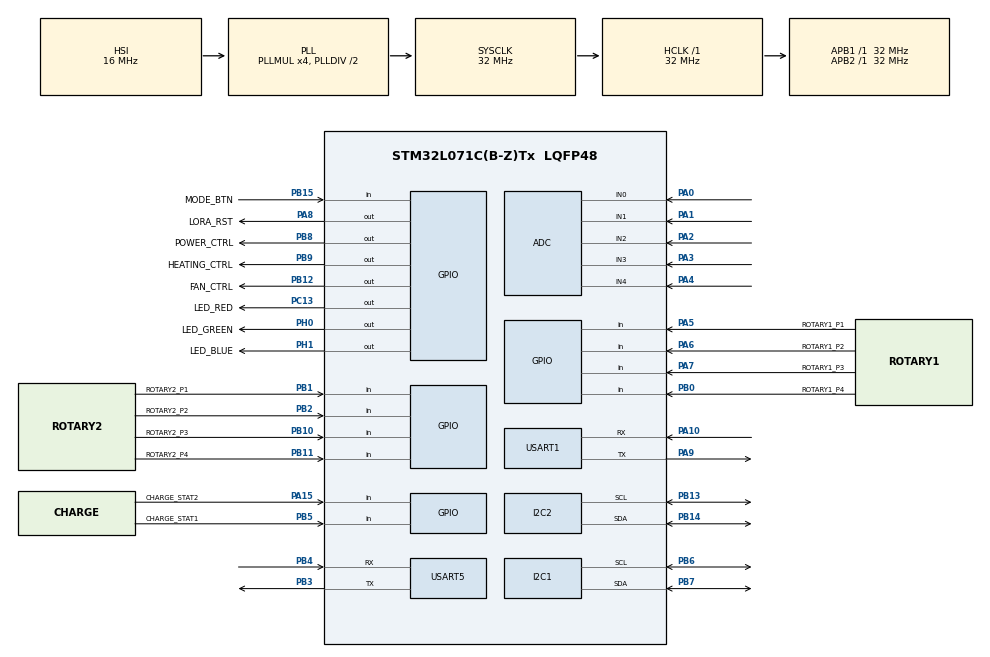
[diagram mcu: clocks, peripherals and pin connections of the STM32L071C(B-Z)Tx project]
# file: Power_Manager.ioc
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ADC.ClockPrescaler=ADC_CLOCK_ASYNC_DIV4
ADC.ContinuousConvMode=DISABLE
ADC.DMAContinuousRequests=DISABLE
ADC.DiscontinuousConvMode=DISABLE
ADC.EOCSelection=ADC_EOC_SEQ_CONV
ADC.EnableAnalogWatchDog=false
ADC.ExternalTrigConv=ADC_EXTERNALTRIGCONV_T3_TRGO
ADC.LowPowerAutoPowerOff=DISABLE
ADC.OversamplingMode=DISABLE
ADC.SamplingTime=ADC_SAMPLETIME_7CYCLES_5
ADC.ScanConvMode=ADC_SCAN_DIRECTION_FORWARD
Dma.ADC.0.Direction=DMA_PERIPH_TO_MEMORY
Dma.ADC.0.Instance=DMA1_Channel1
Dma.ADC.0.MemDataAlignment=DMA_MDATAALIGN_HALFWORD
Dma.ADC.0.MemInc=DMA_MINC_ENABLE
Dma.ADC.0.Mode=DMA_NORMAL
Dma.ADC.0.PeriphDataAlignment=DMA_PDATAALIGN_HALFWORD
Dma.ADC.0.PeriphInc=DMA_PINC_DISABLE
Dma.ADC.0.Priority=DMA_PRIORITY_LOW
Dma.Request0=ADC
I2C1.Timing=0x00707CBB
I2C2.Timing=0x00707CBB
Mcu.Family=STM32L0
Mcu.Name=STM32L071C(B-Z)Tx
Mcu.Package=LQFP48
NVIC.DMA1_Channel1_IRQn=true\:0\:0\:false\:false\:true\:false\:true
NVIC.TIM6_IRQn=true\:0\:0\:false\:false\:true\:true\:true
NVIC.TIM7_IRQn=true\:0\:0\:false\:false\:true\:true\:true
NVIC.USART1_IRQn=true\:0\:0\:false\:false\:true\:true\:true
NVIC.USART4_5_IRQn=true\:0\:0\:false\:false\:true\:true\:true
PA0.Mode=IN0
PA0.Signal=ADC_IN0
PA1.Mode=IN1
PA1.Signal=ADC_IN1
PA10.Mode=Asynchronous
PA10.Signal=USART1_RX
PA13.Mode=Serial_Wire
PA13.Signal=SYS_SWDIO
PA14.Mode=Serial_Wire
PA14.Signal=SYS_SWCLK
PA15.GPIO_Label=CHARGE_STAT2
PA15.Signal=GPIO_Input
PA2.Mode=IN2
PA2.Signal=ADC_IN2
PA3.Mode=IN3
PA3.Signal=ADC_IN3
PA4.Mode=IN4
PA4.Signal=ADC_IN4
PA5.GPIO_Label=ROTARY1_P1
PA5.Signal=GPIO_Input
PA6.GPIO_Label=ROTARY1_P2
PA6.Signal=GPIO_Input
PA7.GPIO_Label=ROTARY1_P3
PA7.Signal=GPIO_Input
PA8.GPIO_Label=LORA_RST
PA8.Signal=GPIO_Output
PA9.Mode=Asynchronous
PA9.Signal=USART1_TX
PB0.GPIO_Label=ROTARY1_P4
PB0.Signal=GPIO_Input
PB1.GPIO_Label=ROTARY2_P1
PB1.Signal=GPIO_Input
PB10.GPIO_Label=ROTARY2_P3
PB10.Signal=GPIO_Input
PB11.GPIO_Label=ROTARY2_P4
PB11.Signal=GPIO_Input
PB12.GPIO_Label=FAN_CTRL
PB12.GPIO_ModeDefaultOutputPP=GPIO_MODE_OUTPUT_PP
PB12.GPIO_PuPd=GPIO_PULLUP
PB12.PinState=GPIO_PIN_RESET
PB12.Signal=GPIO_Output
PB13.Mode=I2C
PB13.Signal=I2C2_SCL
PB14.Mode=I2C
PB14.Signal=I2C2_SDA
PB15.GPIO_Label=MODE_BTN
PB15.GPIO_PuPd=GPIO_PULLUP
PB15.Signal=GPIO_Input
PB2.GPIO_Label=ROTARY2_P2
PB2.Signal=GPIO_Input
PB3.Mode=Asynchronous
PB3.Signal=USART5_TX
PB4.Mode=Asynchronous
PB4.Signal=USART5_RX
PB5.GPIO_Label=CHARGE_STAT1
PB5.Signal=GPIO_Input
PB6.Mode=I2C
PB6.Signal=I2C1_SCL
PB7.Mode=I2C
PB7.Signal=I2C1_SDA
PB8.GPIO_Label=POWER_CTRL
PB8.GPIO_PuPd=GPIO_PULLUP
PB8.PinState=GPIO_PIN_RESET
PB8.Signal=GPIO_Output
PB9.GPIO_Label=HEATING_CTRL
PB9.GPIO_PuPd=GPIO_PULLUP
PB9.PinState=GPIO_PIN_RESET
PB9.Signal=GPIO_Output
PC13.GPIO_Label=LED_RED
PC13.PinState=GPIO_PIN_SET
PC13.Signal=GPIO_Output
PC14-OSC32_IN.Mode=LSE-External-Oscillator
PC14-OSC32_IN.Signal=RCC_OSC32_IN
PC15-OSC32_OUT.Mode=LSE-External-Oscillator
PC15-OSC32_OUT.Signal=RCC_OSC32_OUT
PH0-OSC_IN.GPIO_Label=LED_GREEN
PH0-OSC_IN.PinState=GPIO_PIN_SET
PH0-OSC_IN.Signal=GPIO_Output
PH1-OSC_OUT.GPIO_Label=LED_BLUE
PH1-OSC_OUT.PinState=GPIO_PIN_SET
PH1-OSC_OUT.Signal=GPIO_Output
ProjectManager.HeapSize=0x200
ProjectManager.StackSize=0x400
ProjectManager.TargetToolchain=STM32CubeIDE
RCC.AHBFreq_Value=32000000
RCC.APB1Freq_Value=32000000
RCC.APB1TimFreq_Value=32000000
RCC.APB2Freq_Value=32000000
RCC.APB2TimFreq_Value=32000000
RCC.HCLKFreq_Value=32000000
RCC.HSE_VALUE=8000000
RCC.HSI16_VALUE=16000000
RCC.HSI_VALUE=16000000
RCC.MSI_VALUE=2097000
RCC.PLLMUL=RCC_PLLMUL_4
RCC.SYSCLKFreq_VALUE=32000000
RCC.SYSCLKSource=RCC_SYSCLKSOURCE_PLLCLK
RCC.VCOOutputFreq_Value=64000000
TIM3.Channel-Output\ Compare1\ No\ Output=TIM_CHANNEL_1
TIM3.Period=200-1
TIM3.Prescaler=6400-1
TIM3.TIM_MasterOutputTrigger=TIM_TRGO_UPDATE
TIM6.Period=1000-1
TIM6.Prescaler=32000-1
TIM7.Period=100-1
TIM7.Prescaler=320-1
USART1.VirtualMode-Asynchronous=VM_ASYNC
USART5.VirtualMode-Asynchronous=VM_ASYNC
VP_TIM2_VS_ClockSourceINT.Mode=Internal
VP_TIM3_VS_no_output1.Mode=Output Compare1 No Output
VP_TIM6_VS_ClockSourceINT.Mode=Enable_Timer
VP_TIM7_VS_ClockSourceINT.Mode=Enable_Timer
board=custom

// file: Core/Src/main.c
/* USER CODE BEGIN Header */
/**
  ******************************************************************************
  * @file           : main.c
  * @brief          : Main program body
  ******************************************************************************
  * @attention
  *
  * <h2><center>&copy; Copyright (c) 2021 STMicroelectronics.
  * All rights reserved.</center></h2>
  *
  * This software component is licensed by ST under BSD 3-Clause license,
  * the "License"; You may not use this file except in compliance with the
  * License. You may obtain a copy of the License at:
  *                        opensource.org/licenses/BSD-3-Clause
  *
  ******************************************************************************
  */
/* USER CODE END Header */
#include "main.h"

/* USER CODE BEGIN Includes */
#include "Common.h"
#include "user_process.h"
/* USER CODE END Includes */

ADC_HandleTypeDef hadc;
DMA_HandleTypeDef hdma_adc;

I2C_HandleTypeDef hi2c1;
I2C_HandleTypeDef hi2c2;

TIM_HandleTypeDef htim2;
TIM_HandleTypeDef htim3;
TIM_HandleTypeDef htim6;
TIM_HandleTypeDef htim7;

UART_HandleTypeDef huart1;
UART_HandleTypeDef huart5;

void SystemClock_Config(void);
static void MX_GPIO_Init(void);
static void MX_DMA_Init(void);
static void MX_ADC_Init(void);
static void MX_I2C1_Init(void);
static void MX_I2C2_Init(void);
static void MX_TIM2_Init(void);
static void MX_USART1_UART_Init(void);
static void MX_USART5_UART_Init(void);
static void MX_TIM6_Init(void);
static void MX_TIM7_Init(void);
static void MX_TIM3_Init(void);

/* USER CODE BEGIN 0 */
device_state_t device_state;
/* USER CODE END 0 */

int main(void)
{

  /* MCU Configuration--------------------------------------------------------*/

  /* Reset of all peripherals, Initializes the Flash interface and the Systick. */
  HAL_Init();

  /* Configure the system clock */
  SystemClock_Config();

  /* Initialize all configured peripherals */
  MX_GPIO_Init();
  MX_DMA_Init();
  MX_ADC_Init();
  MX_I2C1_Init();
  MX_I2C2_Init();
  MX_TIM2_Init();
  MX_USART1_UART_Init();
  MX_USART5_UART_Init();
  MX_TIM6_Init();
  MX_TIM7_Init();
  MX_TIM3_Init();
  /* USER CODE BEGIN 2 */

  user_pripheral_init();
  user_driver_init();
  APP_LOGD("Interrupt timer start project");

  /* USER CODE END 2 */

  /* Infinite loop */
  /* USER CODE BEGIN WHILE */
  while (1)
  {
    user_driver_process();
    /* USER CODE END WHILE */

  }
}

void SystemClock_Config(void)
{
  RCC_OscInitTypeDef RCC_OscInitStruct = {0};
  RCC_ClkInitTypeDef RCC_ClkInitStruct = {0};
  RCC_PeriphCLKInitTypeDef PeriphClkInit = {0};

  /** Configure the main internal regulator output voltage
  */
  __HAL_PWR_VOLTAGESCALING_CONFIG(PWR_REGULATOR_VOLTAGE_SCALE1);
  /** Initializes the RCC Oscillators according to the specified parameters
  * in the RCC_OscInitTypeDef structure.
  */
  RCC_OscInitStruct.OscillatorType = RCC_OSCILLATORTYPE_HSI;
  RCC_OscInitStruct.HSIState = RCC_HSI_ON;
  RCC_OscInitStruct.HSICalibrationValue = RCC_HSICALIBRATION_DEFAULT;
  RCC_OscInitStruct.PLL.PLLState = RCC_PLL_ON;
  RCC_OscInitStruct.PLL.PLLSource = RCC_PLLSOURCE_HSI;
  RCC_OscInitStruct.PLL.PLLMUL = RCC_PLLMUL_4;
  RCC_OscInitStruct.PLL.PLLDIV = RCC_PLLDIV_2;
  if (HAL_RCC_OscConfig(&RCC_OscInitStruct) != HAL_OK)
  {
    Error_Handler();
  }
  /** Initializes the CPU, AHB and APB buses clocks
  */
  RCC_ClkInitStruct.ClockType = RCC_CLOCKTYPE_HCLK | RCC_CLOCKTYPE_SYSCLK | RCC_CLOCKTYPE_PCLK1 | RCC_CLOCKTYPE_PCLK2;
  RCC_ClkInitStruct.SYSCLKSource = RCC_SYSCLKSOURCE_PLLCLK;
  RCC_ClkInitStruct.AHBCLKDivider = RCC_SYSCLK_DIV1;
  RCC_ClkInitStruct.APB1CLKDivider = RCC_HCLK_DIV1;
  RCC_ClkInitStruct.APB2CLKDivider = RCC_HCLK_DIV1;

  if (HAL_RCC_ClockConfig(&RCC_ClkInitStruct, FLASH_LATENCY_1) != HAL_OK)
  {
    Error_Handler();
  }
  PeriphClkInit.PeriphClockSelection = RCC_PERIPHCLK_USART1 | RCC_PERIPHCLK_I2C1;
  PeriphClkInit.Usart1ClockSelection = RCC_USART1CLKSOURCE_PCLK2;
  PeriphClkInit.I2c1ClockSelection = RCC_I2C1CLKSOURCE_PCLK1;
  if (HAL_RCCEx_PeriphCLKConfig(&PeriphClkInit) != HAL_OK)
  {
    Error_Handler();
  }
}

static void MX_ADC_Init(void)
{

  ADC_ChannelConfTypeDef sConfig = {0};

  /** Configure the global features of the ADC (Clock, Resolution, Data Alignment and number of conversion)
  */
  hadc.Instance = ADC1;
  hadc.Init.OversamplingMode = DISABLE;
  hadc.Init.ClockPrescaler = ADC_CLOCK_ASYNC_DIV4;
  hadc.Init.Resolution = ADC_RESOLUTION_12B;
  hadc.Init.SamplingTime = ADC_SAMPLETIME_7CYCLES_5;
  hadc.Init.ScanConvMode = ADC_SCAN_DIRECTION_FORWARD;
  hadc.Init.DataAlign = ADC_DATAALIGN_RIGHT;
  hadc.Init.ContinuousConvMode = DISABLE;
  hadc.Init.DiscontinuousConvMode = DISABLE;
  hadc.Init.ExternalTrigConvEdge = ADC_EXTERNALTRIGCONVEDGE_RISING;
  hadc.Init.ExternalTrigConv = ADC_EXTERNALTRIGCONV_T3_TRGO;
  hadc.Init.DMAContinuousRequests = DISABLE;
  hadc.Init.EOCSelection = ADC_EOC_SEQ_CONV;
  hadc.Init.Overrun = ADC_OVR_DATA_PRESERVED;
  hadc.Init.LowPowerAutoWait = DISABLE;
  hadc.Init.LowPowerFrequencyMode = DISABLE;
  hadc.Init.LowPowerAutoPowerOff = DISABLE;
  if (HAL_ADC_Init(&hadc) != HAL_OK)
  {
    Error_Handler();
  }
  /** Configure for the selected ADC regular channel to be converted.
  */
  sConfig.Channel = ADC_CHANNEL_0;
  sConfig.Rank = ADC_RANK_CHANNEL_NUMBER;
  if (HAL_ADC_ConfigChannel(&hadc, &sConfig) != HAL_OK)
  {
    Error_Handler();
  }
  /** Configure for the selected ADC regular channel to be converted.
  */
  sConfig.Channel = ADC_CHANNEL_1;
  if (HAL_ADC_ConfigChannel(&hadc, &sConfig) != HAL_OK)
  {
    Error_Handler();
  }
  /** Configure for the selected ADC regular channel to be converted.
  */
  sConfig.Channel = ADC_CHANNEL_2;
  if (HAL_ADC_ConfigChannel(&hadc, &sConfig) != HAL_OK)
  {
    Error_Handler();
  }
  /** Configure for the selected ADC regular channel to be converted.
  */
  sConfig.Channel = ADC_CHANNEL_3;
  if (HAL_ADC_ConfigChannel(&hadc, &sConfig) != HAL_OK)
  {
    Error_Handler();
  }
  /** Configure for the selected ADC regular channel to be converted.
  */
  sConfig.Channel = ADC_CHANNEL_4;
  if (HAL_ADC_ConfigChannel(&hadc, &sConfig) != HAL_OK)
  {
    Error_Handler();
  }
}

static void MX_I2C1_Init(void)
{

  hi2c1.Instance = I2C1;
  hi2c1.Init.Timing = 0x00707CBB;
  hi2c1.Init.OwnAddress1 = 0;
  hi2c1.Init.AddressingMode = I2C_ADDRESSINGMODE_7BIT;
  hi2c1.Init.DualAddressMode = I2C_DUALADDRESS_DISABLE;
  hi2c1.Init.OwnAddress2 = 0;
  hi2c1.Init.OwnAddress2Masks = I2C_OA2_NOMASK;
  hi2c1.Init.GeneralCallMode = I2C_GENERALCALL_DISABLE;
  hi2c1.Init.NoStretchMode = I2C_NOSTRETCH_DISABLE;
  if (HAL_I2C_Init(&hi2c1) != HAL_OK)
  {
    Error_Handler();
  }
  /** Configure Analogue filter
  */
  if (HAL_I2CEx_ConfigAnalogFilter(&hi2c1, I2C_ANALOGFILTER_ENABLE) != HAL_OK)
  {
    Error_Handler();
  }
  /** Configure Digital filter
  */
  if (HAL_I2CEx_ConfigDigitalFilter(&hi2c1, 0) != HAL_OK)
  {
    Error_Handler();
  }
}

static void MX_I2C2_Init(void)
{

  hi2c2.Instance = I2C2;
  hi2c2.Init.Timing = 0x00707CBB;
  hi2c2.Init.OwnAddress1 = 0;
  hi2c2.Init.AddressingMode = I2C_ADDRESSINGMODE_7BIT;
  hi2c2.Init.DualAddressMode = I2C_DUALADDRESS_DISABLE;
  hi2c2.Init.OwnAddress2 = 0;
  hi2c2.Init.OwnAddress2Masks = I2C_OA2_NOMASK;
  hi2c2.Init.GeneralCallMode = I2C_GENERALCALL_DISABLE;
  hi2c2.Init.NoStretchMode = I2C_NOSTRETCH_DISABLE;
  if (HAL_I2C_Init(&hi2c2) != HAL_OK)
  {
    Error_Handler();
  }
  /** Configure Analogue filter
  */
  if (HAL_I2CEx_ConfigAnalogFilter(&hi2c2, I2C_ANALOGFILTER_ENABLE) != HAL_OK)
  {
    Error_Handler();
  }
  /** Configure Digital filter
  */
  if (HAL_I2CEx_ConfigDigitalFilter(&hi2c2, 0) != HAL_OK)
  {
    Error_Handler();
  }
}

static void MX_TIM2_Init(void)
{

  TIM_ClockConfigTypeDef sClockSourceConfig = {0};
  TIM_MasterConfigTypeDef sMasterConfig = {0};

  htim2.Instance = TIM2;
  htim2.Init.Prescaler = 0;
  htim2.Init.CounterMode = TIM_COUNTERMODE_UP;
  htim2.Init.Period = 65535;
  htim2.Init.ClockDivision = TIM_CLOCKDIVISION_DIV1;
  htim2.Init.AutoReloadPreload = TIM_AUTORELOAD_PRELOAD_DISABLE;
  if (HAL_TIM_Base_Init(&htim2) != HAL_OK)
  {
    Error_Handler();
  }
  sClockSourceConfig.ClockSource = TIM_CLOCKSOURCE_INTERNAL;
  if (HAL_TIM_ConfigClockSource(&htim2, &sClockSourceConfig) != HAL_OK)
  {
    Error_Handler();
  }
  sMasterConfig.MasterOutputTrigger = TIM_TRGO_RESET;
  sMasterConfig.MasterSlaveMode = TIM_MASTERSLAVEMODE_DISABLE;
  if (HAL_TIMEx_MasterConfigSynchronization(&htim2, &sMasterConfig) != HAL_OK)
  {
    Error_Handler();
  }
}

static void MX_TIM3_Init(void)
{

  TIM_MasterConfigTypeDef sMasterConfig = {0};
  TIM_OC_InitTypeDef sConfigOC = {0};

  htim3.Instance = TIM3;
  htim3.Init.Prescaler = 6400 - 1;
  htim3.Init.CounterMode = TIM_COUNTERMODE_UP;
  htim3.Init.Period = 200 - 1;
  htim3.Init.ClockDivision = TIM_CLOCKDIVISION_DIV1;
  htim3.Init.AutoReloadPreload = TIM_AUTORELOAD_PRELOAD_DISABLE;
  if (HAL_TIM_OC_Init(&htim3) != HAL_OK)
  {
    Error_Handler();
  }
  sMasterConfig.MasterOutputTrigger = TIM_TRGO_UPDATE;
  sMasterConfig.MasterSlaveMode = TIM_MASTERSLAVEMODE_DISABLE;
  if (HAL_TIMEx_MasterConfigSynchronization(&htim3, &sMasterConfig) != HAL_OK)
  {
    Error_Handler();
  }
  sConfigOC.OCMode = TIM_OCMODE_TIMING;
  sConfigOC.Pulse = 0;
  sConfigOC.OCPolarity = TIM_OCPOLARITY_HIGH;
  sConfigOC.OCFastMode = TIM_OCFAST_DISABLE;
  if (HAL_TIM_OC_ConfigChannel(&htim3, &sConfigOC, TIM_CHANNEL_1) != HAL_OK)
  {
    Error_Handler();
  }
}

static void MX_TIM6_Init(void)
{

  TIM_MasterConfigTypeDef sMasterConfig = {0};

  htim6.Instance = TIM6;
  htim6.Init.Prescaler = 32000 - 1;
  htim6.Init.CounterMode = TIM_COUNTERMODE_UP;
  htim6.Init.Period = 1000 - 1;
  htim6.Init.AutoReloadPreload = TIM_AUTORELOAD_PRELOAD_DISABLE;
  if (HAL_TIM_Base_Init(&htim6) != HAL_OK)
  {
    Error_Handler();
  }
  sMasterConfig.MasterOutputTrigger = TIM_TRGO_RESET;
  sMasterConfig.MasterSlaveMode = TIM_MASTERSLAVEMODE_DISABLE;
  if (HAL_TIMEx_MasterConfigSynchronization(&htim6, &sMasterConfig) != HAL_OK)
  {
    Error_Handler();
  }
}

static void MX_TIM7_Init(void)
{

  TIM_MasterConfigTypeDef sMasterConfig = {0};

  htim7.Instance = TIM7;
  htim7.Init.Prescaler = 320 - 1;
  htim7.Init.CounterMode = TIM_COUNTERMODE_UP;
  htim7.Init.Period = 100 - 1;
  htim7.Init.AutoReloadPreload = TIM_AUTORELOAD_PRELOAD_DISABLE;
  if (HAL_TIM_Base_Init(&htim7) != HAL_OK)
  {
    Error_Handler();
  }
  sMasterConfig.MasterOutputTrigger = TIM_TRGO_RESET;
  sMasterConfig.MasterSlaveMode = TIM_MASTERSLAVEMODE_DISABLE;
  if (HAL_TIMEx_MasterConfigSynchronization(&htim7, &sMasterConfig) != HAL_OK)
  {
    Error_Handler();
  }
}

static void MX_USART1_UART_Init(void)
{

  huart1.Instance = USART1;
  huart1.Init.BaudRate = 115200;
  huart1.Init.WordLength = UART_WORDLENGTH_8B;
  huart1.Init.StopBits = UART_STOPBITS_1;
  huart1.Init.Parity = UART_PARITY_NONE;
  huart1.Init.Mode = UART_MODE_TX_RX;
  huart1.Init.HwFlowCtl = UART_HWCONTROL_NONE;
  huart1.Init.OverSampling = UART_OVERSAMPLING_16;
  huart1.Init.OneBitSampling = UART_ONE_BIT_SAMPLE_DISABLE;
  huart1.AdvancedInit.AdvFeatureInit = UART_ADVFEATURE_NO_INIT;
  if (HAL_UART_Init(&huart1) != HAL_OK)
  {
    Error_Handler();
  }
}

static void MX_USART5_UART_Init(void)
{

  huart5.Instance = USART5;
  huart5.Init.BaudRate = 115200;
  huart5.Init.WordLength = UART_WORDLENGTH_8B;
  huart5.Init.StopBits = UART_STOPBITS_1;
  huart5.Init.Parity = UART_PARITY_NONE;
  huart5.Init.Mode = UART_MODE_TX_RX;
  huart5.Init.HwFlowCtl = UART_HWCONTROL_NONE;
  huart5.Init.OverSampling = UART_OVERSAMPLING_16;
  huart5.Init.OneBitSampling = UART_ONE_BIT_SAMPLE_DISABLE;
  huart5.AdvancedInit.AdvFeatureInit = UART_ADVFEATURE_NO_INIT;
  if (HAL_UART_Init(&huart5) != HAL_OK)
  {
    Error_Handler();
  }
}

static void MX_DMA_Init(void)
{

  /* DMA controller clock enable */
  __HAL_RCC_DMA1_CLK_ENABLE();

  /* DMA interrupt init */
  /* DMA1_Channel1_IRQn interrupt configuration */
  HAL_NVIC_SetPriority(DMA1_Channel1_IRQn, 0, 0);
  HAL_NVIC_EnableIRQ(DMA1_Channel1_IRQn);
}

static void MX_GPIO_Init(void)
{
  GPIO_InitTypeDef GPIO_InitStruct = {0};

  /* GPIO Ports Clock Enable */
  __HAL_RCC_GPIOC_CLK_ENABLE();
  __HAL_RCC_GPIOH_CLK_ENABLE();
  __HAL_RCC_GPIOA_CLK_ENABLE();
  __HAL_RCC_GPIOB_CLK_ENABLE();

  /*Configure GPIO pin Output Level */
  HAL_GPIO_WritePin(LED_RED_GPIO_Port, LED_RED_Pin, GPIO_PIN_SET);

  /*Configure GPIO pin Output Level */
  HAL_GPIO_WritePin(GPIOH, LED_GREEN_Pin | LED_BLUE_Pin, GPIO_PIN_SET);

  /*Configure GPIO pin Output Level */
  HAL_GPIO_WritePin(GPIOB, FAN_CTRL_Pin | POWER_CTRL_Pin | HEATING_CTRL_Pin, GPIO_PIN_RESET);

  /*Configure GPIO pin Output Level */
  HAL_GPIO_WritePin(LORA_RST_GPIO_Port, LORA_RST_Pin, GPIO_PIN_RESET);

  /*Configure GPIO pin : LED_RED_Pin */
  GPIO_InitStruct.Pin = LED_RED_Pin;
  GPIO_InitStruct.Mode = GPIO_MODE_OUTPUT_PP;
  GPIO_InitStruct.Pull = GPIO_NOPULL;
  GPIO_InitStruct.Speed = GPIO_SPEED_FREQ_LOW;
  HAL_GPIO_Init(LED_RED_GPIO_Port, &GPIO_InitStruct);

  /*Configure GPIO pins : LED_GREEN_Pin LED_BLUE_Pin */
  GPIO_InitStruct.Pin = LED_GREEN_Pin | LED_BLUE_Pin;
  GPIO_InitStruct.Mode = GPIO_MODE_OUTPUT_PP;
  GPIO_InitStruct.Pull = GPIO_NOPULL;
  GPIO_InitStruct.Speed = GPIO_SPEED_FREQ_LOW;
  HAL_GPIO_Init(GPIOH, &GPIO_InitStruct);

  /*Configure GPIO pins : ROTARY1_P1_Pin ROTARY1_P2_Pin ROTARY1_P3_Pin CHARGE_STAT2_Pin */
  GPIO_InitStruct.Pin = ROTARY1_P1_Pin | ROTARY1_P2_Pin | ROTARY1_P3_Pin | CHARGE_STAT2_Pin;
  GPIO_InitStruct.Mode = GPIO_MODE_INPUT;
  GPIO_InitStruct.Pull = GPIO_NOPULL;
  HAL_GPIO_Init(GPIOA, &GPIO_InitStruct);

  /*Configure GPIO pins : ROTARY1_P4_Pin ROTARY2_P1_Pin ROTARY2_P2_Pin ROTARY2_P3_Pin
                           ROTARY2_P4_Pin CHARGE_STAT1_Pin */
  GPIO_InitStruct.Pin = ROTARY1_P4_Pin | ROTARY2_P1_Pin | ROTARY2_P2_Pin | ROTARY2_P3_Pin | ROTARY2_P4_Pin | CHARGE_STAT1_Pin;
  GPIO_InitStruct.Mode = GPIO_MODE_INPUT;
  GPIO_InitStruct.Pull = GPIO_NOPULL;
  HAL_GPIO_Init(GPIOB, &GPIO_InitStruct);

  /*Configure GPIO pins : FAN_CTRL_Pin POWER_CTRL_Pin HEATING_CTRL_Pin */
  GPIO_InitStruct.Pin = FAN_CTRL_Pin | POWER_CTRL_Pin | HEATING_CTRL_Pin;
  GPIO_InitStruct.Mode = GPIO_MODE_OUTPUT_PP;
  GPIO_InitStruct.Pull = GPIO_PULLUP;
  GPIO_InitStruct.Speed = GPIO_SPEED_FREQ_LOW;
  HAL_GPIO_Init(GPIOB, &GPIO_InitStruct);

  /*Configure GPIO pin : MODE_BTN_Pin */
  GPIO_InitStruct.Pin = MODE_BTN_Pin;
  GPIO_InitStruct.Mode = GPIO_MODE_INPUT;
  GPIO_InitStruct.Pull = GPIO_PULLUP;
  HAL_GPIO_Init(MODE_BTN_GPIO_Port, &GPIO_InitStruct);

  /*Configure GPIO pin : LORA_RST_Pin */
  GPIO_InitStruct.Pin = LORA_RST_Pin;
  GPIO_InitStruct.Mode = GPIO_MODE_OUTPUT_PP;
  GPIO_InitStruct.Pull = GPIO_NOPULL;
  GPIO_InitStruct.Speed = GPIO_SPEED_FREQ_LOW;
  HAL_GPIO_Init(LORA_RST_GPIO_Port, &GPIO_InitStruct);
}

void Error_Handler(void)
{
  __disable_irq();
  while (1)
  {
  }
}

/************************ (C) COPYRIGHT STMicroelectronics *****END OF FILE****/
